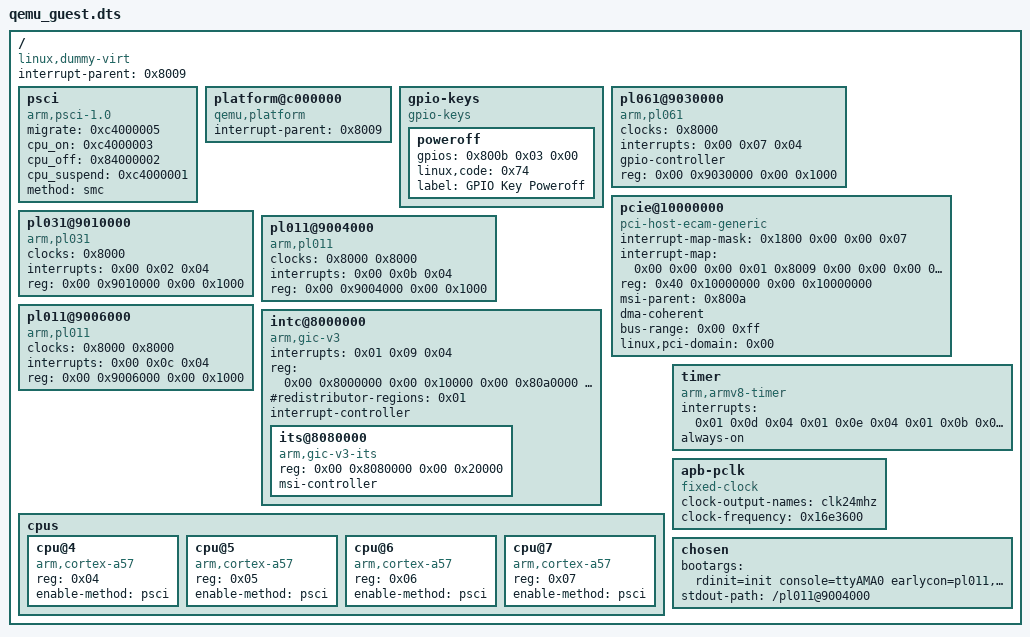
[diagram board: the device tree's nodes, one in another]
/dts-v1/;

/ {
	interrupt-parent = <0x8009>;
	#size-cells = <0x02>;
	#address-cells = <0x02>;
	compatible = "linux,dummy-virt";

	psci {
		migrate = <0xc4000005>;
		cpu_on = <0xc4000003>;
		cpu_off = <0x84000002>;
		cpu_suspend = <0xc4000001>;
		method = "smc";
		compatible = "arm,psci-1.0\0arm,psci-0.2\0arm,psci";
	};

	platform@c000000 {
		interrupt-parent = <0x8009>;
		ranges = <0x00 0x00 0xc000000 0x2000000>;
		#address-cells = <0x01>;
		#size-cells = <0x01>;
		compatible = "qemu,platform\0simple-bus";
	};

	gpio-keys {
		#address-cells = <0x01>;
		#size-cells = <0x00>;
		compatible = "gpio-keys";

		poweroff {
			gpios = <0x800b 0x03 0x00>;
			linux,code = <0x74>;
			label = "GPIO Key Poweroff";
		};
	};

	pl061@9030000 {
		phandle = <0x800b>;
		clock-names = "apb_pclk";
		clocks = <0x8000>;
		interrupts = <0x00 0x07 0x04>;
		gpio-controller;
		#gpio-cells = <0x02>;
		compatible = "arm,pl061\0arm,primecell";
		reg = <0x00 0x9030000 0x00 0x1000>;
	};

	pcie@10000000 {
		interrupt-map-mask = <0x1800 0x00 0x00 0x07>;
		interrupt-map = <0x00 0x00 0x00 0x01 0x8009 0x00 0x00 0x00 0x03 0x04 0x00 0x00 0x00 0x02 0x8009 0x00 0x00 0x00 0x04 0x04 0x00 0x00 0x00 0x03 0x8009 0x00 0x00 0x00 0x05 0x04 0x00 0x00 0x00 0x04 0x8009 0x00 0x00 0x00 0x06 0x04 0x800 0x00 0x00 0x01 0x8009 0x00 0x00 0x00 0x04 0x04 0x800 0x00 0x00 0x02 0x8009 0x00 0x00 0x00 0x05 0x04 0x800 0x00 0x00 0x03 0x8009 0x00 0x00 0x00 0x06 0x04 0x800 0x00 0x00 0x04 0x8009 0x00 0x00 0x00 0x03 0x04 0x1000 0x00 0x00 0x01 0x8009 0x00 0x00 0x00 0x05 0x04 0x1000 0x00 0x00 0x02 0x8009 0x00 0x00 0x00 0x06 0x04 0x1000 0x00 0x00 0x03 0x8009 0x00 0x00 0x00 0x03 0x04 0x1000 0x00 0x00 0x04 0x8009 0x00 0x00 0x00 0x04 0x04 0x1800 0x00 0x00 0x01 0x8009 0x00 0x00 0x00 0x06 0x04 0x1800 0x00 0x00 0x02 0x8009 0x00 0x00 0x00 0x03 0x04 0x1800 0x00 0x00 0x03 0x8009 0x00 0x00 0x00 0x04 0x04 0x1800 0x00 0x00 0x04 0x8009 0x00 0x00 0x00 0x05 0x04>;
		#interrupt-cells = <0x01>;
		ranges = <0x1000000 0x00 0x00 0x00 0x3eff0000 0x00 0x10000 0x2000000 0x00 0x10000000 0x00 0x10000000 0x00 0x2eff0000 0x3000000 0x80 0x00 0x80 0x00 0x80 0x00>;
		reg = <0x40 0x10000000 0x00 0x10000000>;
		msi-parent = <0x800a>;
		dma-coherent;
		bus-range = <0x00 0xff>;
		linux,pci-domain = <0x00>;
		#size-cells = <0x02>;
		#address-cells = <0x03>;
		device_type = "pci";
		compatible = "pci-host-ecam-generic";
	};

	pl031@9010000 {
		clock-names = "apb_pclk";
		clocks = <0x8000>;
		interrupts = <0x00 0x02 0x04>;
		reg = <0x00 0x9010000 0x00 0x1000>;
		compatible = "arm,pl031\0arm,primecell";
	};

	pl011@9004000 {
		clock-names = "uartclk\0apb_pclk";
		clocks = <0x8000 0x8000>;
		interrupts = <0x00 0x0b 0x04>;
		reg = <0x00 0x9004000 0x00 0x1000>;
		compatible = "arm,pl011\0arm,primecell";
	};

	pl011@9006000 {
		clock-names = "uartclk\0apb_pclk";
		clocks = <0x8000 0x8000>;
		interrupts = <0x00 0x0c 0x04>;
		reg = <0x00 0x9006000 0x00 0x1000>;
		compatible = "arm,pl011\0arm,primecell";
	};

	intc@8000000 {
		phandle = <0x8009>;
		interrupts = <0x01 0x09 0x04>;
		reg = <0x00 0x8000000 0x00 0x10000 0x00 0x80a0000 0x00 0xf60000>;
		#redistributor-regions = <0x01>;
		compatible = "arm,gic-v3";
		ranges;
		#size-cells = <0x02>;
		#address-cells = <0x02>;
		interrupt-controller;
		#interrupt-cells = <0x03>;

		its@8080000 {
			phandle = <0x800a>;
			reg = <0x00 0x8080000 0x00 0x20000>;
			msi-controller;
			compatible = "arm,gic-v3-its";
		};
	};

	cpus {
		#size-cells = <0x00>;
		#address-cells = <0x01>;

		cpu@4 {
			phandle = <0x8004>;
			reg = <0x04>;
			enable-method = "psci";
			compatible = "arm,cortex-a57";
			device_type = "cpu";
		};

		cpu@5 {
			phandle = <0x8003>;
			reg = <0x05>;
			enable-method = "psci";
			compatible = "arm,cortex-a57";
			device_type = "cpu";
		};

		cpu@6 {
			phandle = <0x8002>;
			reg = <0x06>;
			enable-method = "psci";
			compatible = "arm,cortex-a57";
			device_type = "cpu";
		};

		cpu@7 {
			phandle = <0x8001>;
			reg = <0x07>;
			enable-method = "psci";
			compatible = "arm,cortex-a57";
			device_type = "cpu";
		};
	};

	timer {
		interrupts = <0x01 0x0d 0x04 0x01 0x0e 0x04 0x01 0x0b 0x04 0x01 0x0a 0x04>;
		always-on;
		compatible = "arm,armv8-timer\0arm,armv7-timer";
	};

	apb-pclk {
		phandle = <0x8000>;
		clock-output-names = "clk24mhz";
		clock-frequency = <0x16e3600>;
		#clock-cells = <0x00>;
		compatible = "fixed-clock";
	};

	chosen {
		bootargs = "rdinit=init console=ttyAMA0 earlycon=pl011,mmio32,0x9004000 maxcpus=1";
		stdout-path = "/pl011@9004000";
	};
};
